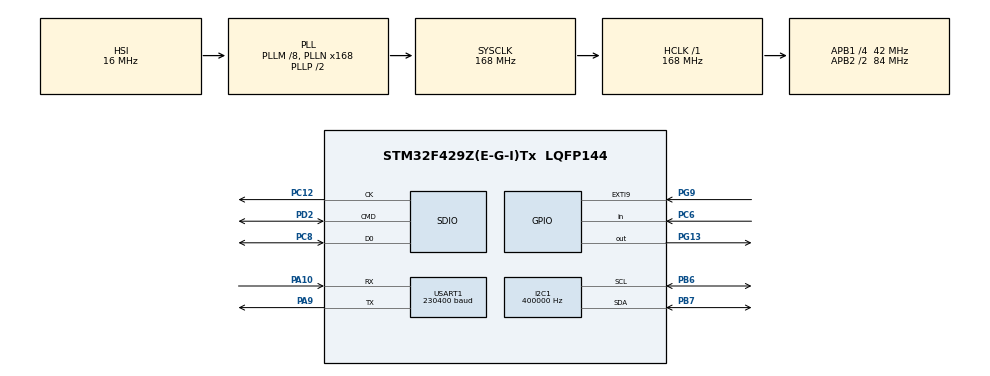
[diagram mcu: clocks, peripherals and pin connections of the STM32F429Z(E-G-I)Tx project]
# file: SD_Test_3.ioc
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FATFS._MAX_SS=4096
I2C1.AddressingMode=I2C_ADDRESSINGMODE_7BIT
I2C1.ClockSpeed=400000
I2C1.I2C_Mode=I2C_Fast
Mcu.Family=STM32F4
Mcu.Name=STM32F429Z(E-G-I)Tx
Mcu.Package=LQFP144
NVIC.EXTI9_5_IRQn=true\:2\:0\:true\:false\:true\:true
NVIC.I2C1_EV_IRQn=true\:3\:0\:true\:false\:true\:true
NVIC.PriorityGroup=NVIC_PRIORITYGROUP_4
NVIC.RCC_IRQn=true\:0\:0\:true\:false\:true\:true
NVIC.TIM2_IRQn=true\:4\:0\:true\:false\:true\:true
NVIC.USART1_IRQn=true\:1\:0\:true\:false\:true\:true
PA10.Mode=Asynchronous
PA10.Signal=USART1_RX
PA13.Mode=Serial_Wire
PA13.Signal=SYS_JTMS-SWDIO
PA14.Mode=Serial_Wire
PA14.Signal=SYS_JTCK-SWCLK
PA9.Mode=Asynchronous
PA9.Signal=USART1_TX
PB6.Mode=I2C
PB6.Signal=I2C1_SCL
PB7.Mode=I2C
PB7.Signal=I2C1_SDA
PC12.Mode=SD_1_bit
PC12.Signal=SDIO_CK
PC6.Signal=GPIO_Input
PC8.GPIO_PuPd=GPIO_PULLUP
PC8.Mode=SD_1_bit
PC8.Signal=SDIO_D0
PD2.GPIO_PuPd=GPIO_PULLUP
PD2.Mode=SD_1_bit
PD2.Signal=SDIO_CMD
PG13.Signal=GPIO_Output
PG9.Signal=GPXTI9
ProjectManager.HeapSize=0x200
ProjectManager.StackSize=0x400
ProjectManager.TargetToolchain=MDK-ARM V5
RCC.48MHZClocksFreq_Value=48000000
RCC.AHBFreq_Value=168000000
RCC.APB1CLKDivider=RCC_HCLK_DIV4
RCC.APB1Freq_Value=42000000
RCC.APB1TimFreq_Value=84000000
RCC.APB2CLKDivider=RCC_HCLK_DIV2
RCC.APB2Freq_Value=84000000
RCC.APB2TimFreq_Value=168000000
RCC.CortexFreq_Value=168000000
RCC.HCLKFreq_Value=168000000
RCC.HSE_VALUE=25000000
RCC.HSI_VALUE=16000000
RCC.LSE_VALUE=32768
RCC.PLLM=8
RCC.PLLN=168
RCC.PLLQ=7
RCC.SYSCLKFreq_VALUE=168000000
RCC.SYSCLKSource=RCC_SYSCLKSOURCE_PLLCLK
RCC.VCOOutputFreq_Value=336000000
TIM2.Period=130
TIM2.Prescaler=8400
USART1.BaudRate=230400
USART1.VirtualMode=VM_ASYNC
VP_FATFS_VS_SDIO.Mode=SDIO
VP_TIM2_VS_ClockSourceINT.Mode=Internal
board=SD_Test_3

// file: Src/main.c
/**
  ******************************************************************************
  * File Name          : main.c
  * Description        : Main program body
  ******************************************************************************
  * This notice applies to any and all portions of this file
  * that are not between comment pairs USER CODE BEGIN and
  * USER CODE END. Other portions of this file, whether
  * inserted by the user or by software development tools
  * are owned by their respective copyright owners.
  *
  * Copyright (c) 2018 STMicroelectronics International N.V.
  * All rights reserved.
  *
  * Redistribution and use in source and binary forms, with or without
  * modification, are permitted, provided that the following conditions are met:
  *
  * 1. Redistribution of source code must retain the above copyright notice,
  *    this list of conditions and the following disclaimer.
  * 2. Redistributions in binary form must reproduce the above copyright notice,
  *    this list of conditions and the following disclaimer in the documentation
  *    and/or other materials provided with the distribution.
  * 3. Neither the name of STMicroelectronics nor the names of other
  *    contributors to this software may be used to endorse or promote products
  *    derived from this software without specific written permission.
  * 4. This software, including modifications and/or derivative works of this
  *    software, must execute solely and exclusively on microcontroller or
  *    microprocessor devices manufactured by or for STMicroelectronics.
  * 5. Redistribution and use of this software other than as permitted under
  *    this license is void and will automatically terminate your rights under
  *    this license.
  *
  * THIS SOFTWARE IS PROVIDED BY STMICROELECTRONICS AND CONTRIBUTORS "AS IS"
  * AND ANY EXPRESS, IMPLIED OR STATUTORY WARRANTIES, INCLUDING, BUT NOT
  * LIMITED TO, THE IMPLIED WARRANTIES OF MERCHANTABILITY, FITNESS FOR A
  * PARTICULAR PURPOSE AND NON-INFRINGEMENT OF THIRD PARTY INTELLECTUAL PROPERTY
  * RIGHTS ARE DISCLAIMED TO THE FULLEST EXTENT PERMITTED BY LAW. IN NO EVENT
  * SHALL STMICROELECTRONICS OR CONTRIBUTORS BE LIABLE FOR ANY DIRECT, INDIRECT,
  * INCIDENTAL, SPECIAL, EXEMPLARY, OR CONSEQUENTIAL DAMAGES (INCLUDING, BUT NOT
  * LIMITED TO, PROCUREMENT OF SUBSTITUTE GOODS OR SERVICES; LOSS OF USE, DATA,
  * OR PROFITS; OR BUSINESS INTERRUPTION) HOWEVER CAUSED AND ON ANY THEORY OF
  * LIABILITY, WHETHER IN CONTRACT, STRICT LIABILITY, OR TORT (INCLUDING
  * NEGLIGENCE OR OTHERWISE) ARISING IN ANY WAY OUT OF THE USE OF THIS SOFTWARE,
  * EVEN IF ADVISED OF THE POSSIBILITY OF SUCH DAMAGE.
  *
  ******************************************************************************
  */
#include "main.h"
#include "stm32f4xx_hal.h"
#include "fatfs.h"

/* USER CODE BEGIN Includes */
#include "MPU9255.h"
/* USER CODE END Includes */

I2C_HandleTypeDef hi2c1;

SD_HandleTypeDef hsd;

TIM_HandleTypeDef htim2;

UART_HandleTypeDef huart1;

/* USER CODE BEGIN PV */
/* Private variables ---------------------------------------------------------*/
FATFS SDFatFs;
FIL MyFile;
extern char SD_Path[4];
int16_t accel[3], gyro[3];
/* USER CODE END PV */

void SystemClock_Config(void);
static void MX_GPIO_Init(void);
static void MX_SDIO_SD_Init(void);
static void MX_I2C1_Init(void);
static void MX_USART1_UART_Init(void);
static void MX_TIM2_Init(void);

/* USER CODE BEGIN PFP */
/* Private function prototypes -----------------------------------------------*/

/* USER CODE END PFP */

int main(void)
{

  /* MCU Configuration----------------------------------------------------------*/

  /* Reset of all peripherals, Initializes the Flash interface and the Systick. */
  HAL_Init();

  /* Configure the system clock */
  SystemClock_Config();

  /* Initialize all configured peripherals */
  MX_GPIO_Init();
  MX_SDIO_SD_Init();
  MX_FATFS_Init();
  MX_I2C1_Init();
  MX_USART1_UART_Init();
  MX_TIM2_Init();

  /* USER CODE BEGIN 2 */
	HAL_NVIC_DisableIRQ(EXTI9_5_IRQn);
	USART1->CR1 |= USART_CR1_RXNEIE;

	while(HAL_GPIO_ReadPin(GPIOC, GPIO_PIN_6) == SET)
	{
		HAL_GPIO_TogglePin(GPIOG, GPIO_PIN_13);
		HAL_Delay(200);
	}
	HAL_SD_Init(&hsd);
	HAL_SD_InitCard(&hsd);

  /* USER CODE END 2 */

  /* Infinite loop */
  while (1)
  {

  }

}

/** System Clock Configuration
*/
void SystemClock_Config(void)
{

  RCC_OscInitTypeDef RCC_OscInitStruct;
  RCC_ClkInitTypeDef RCC_ClkInitStruct;

    /**Configure the main internal regulator output voltage
    */
  __HAL_RCC_PWR_CLK_ENABLE();

  __HAL_PWR_VOLTAGESCALING_CONFIG(PWR_REGULATOR_VOLTAGE_SCALE1);

    /**Initializes the CPU, AHB and APB busses clocks
    */
  RCC_OscInitStruct.OscillatorType = RCC_OSCILLATORTYPE_HSI;
  RCC_OscInitStruct.HSIState = RCC_HSI_ON;
  RCC_OscInitStruct.HSICalibrationValue = 16;
  RCC_OscInitStruct.PLL.PLLState = RCC_PLL_ON;
  RCC_OscInitStruct.PLL.PLLSource = RCC_PLLSOURCE_HSI;
  RCC_OscInitStruct.PLL.PLLM = 8;
  RCC_OscInitStruct.PLL.PLLN = 168;
  RCC_OscInitStruct.PLL.PLLP = RCC_PLLP_DIV2;
  RCC_OscInitStruct.PLL.PLLQ = 7;
  if (HAL_RCC_OscConfig(&RCC_OscInitStruct) != HAL_OK)
  {
    _Error_Handler(__FILE__, __LINE__);
  }

    /**Initializes the CPU, AHB and APB busses clocks
    */
  RCC_ClkInitStruct.ClockType = RCC_CLOCKTYPE_HCLK|RCC_CLOCKTYPE_SYSCLK
                              |RCC_CLOCKTYPE_PCLK1|RCC_CLOCKTYPE_PCLK2;
  RCC_ClkInitStruct.SYSCLKSource = RCC_SYSCLKSOURCE_PLLCLK;
  RCC_ClkInitStruct.AHBCLKDivider = RCC_SYSCLK_DIV1;
  RCC_ClkInitStruct.APB1CLKDivider = RCC_HCLK_DIV4;
  RCC_ClkInitStruct.APB2CLKDivider = RCC_HCLK_DIV2;

  if (HAL_RCC_ClockConfig(&RCC_ClkInitStruct, FLASH_LATENCY_5) != HAL_OK)
  {
    _Error_Handler(__FILE__, __LINE__);
  }

    /**Configure the Systick interrupt time
    */
  HAL_SYSTICK_Config(HAL_RCC_GetHCLKFreq()/1000);

    /**Configure the Systick
    */
  HAL_SYSTICK_CLKSourceConfig(SYSTICK_CLKSOURCE_HCLK);

  /* SysTick_IRQn interrupt configuration */
  HAL_NVIC_SetPriority(SysTick_IRQn, 0, 0);
}

/* I2C1 init function */
static void MX_I2C1_Init(void)
{

  hi2c1.Instance = I2C1;
  hi2c1.Init.ClockSpeed = 400000;
  hi2c1.Init.DutyCycle = I2C_DUTYCYCLE_2;
  hi2c1.Init.OwnAddress1 = 0;
  hi2c1.Init.AddressingMode = I2C_ADDRESSINGMODE_7BIT;
  hi2c1.Init.DualAddressMode = I2C_DUALADDRESS_DISABLE;
  hi2c1.Init.OwnAddress2 = 0;
  hi2c1.Init.GeneralCallMode = I2C_GENERALCALL_DISABLE;
  hi2c1.Init.NoStretchMode = I2C_NOSTRETCH_DISABLE;
  if (HAL_I2C_Init(&hi2c1) != HAL_OK)
  {
    _Error_Handler(__FILE__, __LINE__);
  }

}

/* SDIO init function */
static void MX_SDIO_SD_Init(void)
{

  hsd.Instance = SDIO;
  hsd.Init.ClockEdge = SDIO_CLOCK_EDGE_RISING;
  hsd.Init.ClockBypass = SDIO_CLOCK_BYPASS_DISABLE;
  hsd.Init.ClockPowerSave = SDIO_CLOCK_POWER_SAVE_DISABLE;
  hsd.Init.BusWide = SDIO_BUS_WIDE_1B;
  hsd.Init.HardwareFlowControl = SDIO_HARDWARE_FLOW_CONTROL_DISABLE;
  hsd.Init.ClockDiv = 0;

}

/* TIM2 init function */
static void MX_TIM2_Init(void)
{

  TIM_ClockConfigTypeDef sClockSourceConfig;
  TIM_MasterConfigTypeDef sMasterConfig;

  htim2.Instance = TIM2;
  htim2.Init.Prescaler = 8400;
  htim2.Init.CounterMode = TIM_COUNTERMODE_UP;
  htim2.Init.Period = 130;
  htim2.Init.ClockDivision = TIM_CLOCKDIVISION_DIV1;
  if (HAL_TIM_Base_Init(&htim2) != HAL_OK)
  {
    _Error_Handler(__FILE__, __LINE__);
  }

  sClockSourceConfig.ClockSource = TIM_CLOCKSOURCE_INTERNAL;
  if (HAL_TIM_ConfigClockSource(&htim2, &sClockSourceConfig) != HAL_OK)
  {
    _Error_Handler(__FILE__, __LINE__);
  }

  sMasterConfig.MasterOutputTrigger = TIM_TRGO_RESET;
  sMasterConfig.MasterSlaveMode = TIM_MASTERSLAVEMODE_DISABLE;
  if (HAL_TIMEx_MasterConfigSynchronization(&htim2, &sMasterConfig) != HAL_OK)
  {
    _Error_Handler(__FILE__, __LINE__);
  }

}

/* USART1 init function */
static void MX_USART1_UART_Init(void)
{

  huart1.Instance = USART1;
  huart1.Init.BaudRate = 230400;
  huart1.Init.WordLength = UART_WORDLENGTH_8B;
  huart1.Init.StopBits = UART_STOPBITS_1;
  huart1.Init.Parity = UART_PARITY_NONE;
  huart1.Init.Mode = UART_MODE_TX_RX;
  huart1.Init.HwFlowCtl = UART_HWCONTROL_NONE;
  huart1.Init.OverSampling = UART_OVERSAMPLING_16;
  if (HAL_UART_Init(&huart1) != HAL_OK)
  {
    _Error_Handler(__FILE__, __LINE__);
  }

}

/** Configure pins as
        * Analog
        * Input
        * Output
        * EVENT_OUT
        * EXTI
*/
static void MX_GPIO_Init(void)
{

  GPIO_InitTypeDef GPIO_InitStruct;

  /* GPIO Ports Clock Enable */
  __HAL_RCC_GPIOC_CLK_ENABLE();
  __HAL_RCC_GPIOA_CLK_ENABLE();
  __HAL_RCC_GPIOD_CLK_ENABLE();
  __HAL_RCC_GPIOG_CLK_ENABLE();
  __HAL_RCC_GPIOB_CLK_ENABLE();

  /*Configure GPIO pin Output Level */
  HAL_GPIO_WritePin(GPIOG, GPIO_PIN_13, GPIO_PIN_RESET);

  /*Configure GPIO pin : PC6 */
  GPIO_InitStruct.Pin = GPIO_PIN_6;
  GPIO_InitStruct.Mode = GPIO_MODE_INPUT;
  GPIO_InitStruct.Pull = GPIO_NOPULL;
  HAL_GPIO_Init(GPIOC, &GPIO_InitStruct);

  /*Configure GPIO pin : PG9 */
  GPIO_InitStruct.Pin = GPIO_PIN_9;
  GPIO_InitStruct.Mode = GPIO_MODE_IT_RISING;
  GPIO_InitStruct.Pull = GPIO_NOPULL;
  HAL_GPIO_Init(GPIOG, &GPIO_InitStruct);

  /*Configure GPIO pin : PG13 */
  GPIO_InitStruct.Pin = GPIO_PIN_13;
  GPIO_InitStruct.Mode = GPIO_MODE_OUTPUT_PP;
  GPIO_InitStruct.Pull = GPIO_NOPULL;
  GPIO_InitStruct.Speed = GPIO_SPEED_FREQ_LOW;
  HAL_GPIO_Init(GPIOG, &GPIO_InitStruct);

  /* EXTI interrupt init*/
  HAL_NVIC_SetPriority(EXTI9_5_IRQn, 2, 0);
  HAL_NVIC_EnableIRQ(EXTI9_5_IRQn);

}

void _Error_Handler(char * file, int line)
{
  while(1)
  {
  }
}

/************************ (C) COPYRIGHT STMicroelectronics *****END OF FILE****/
